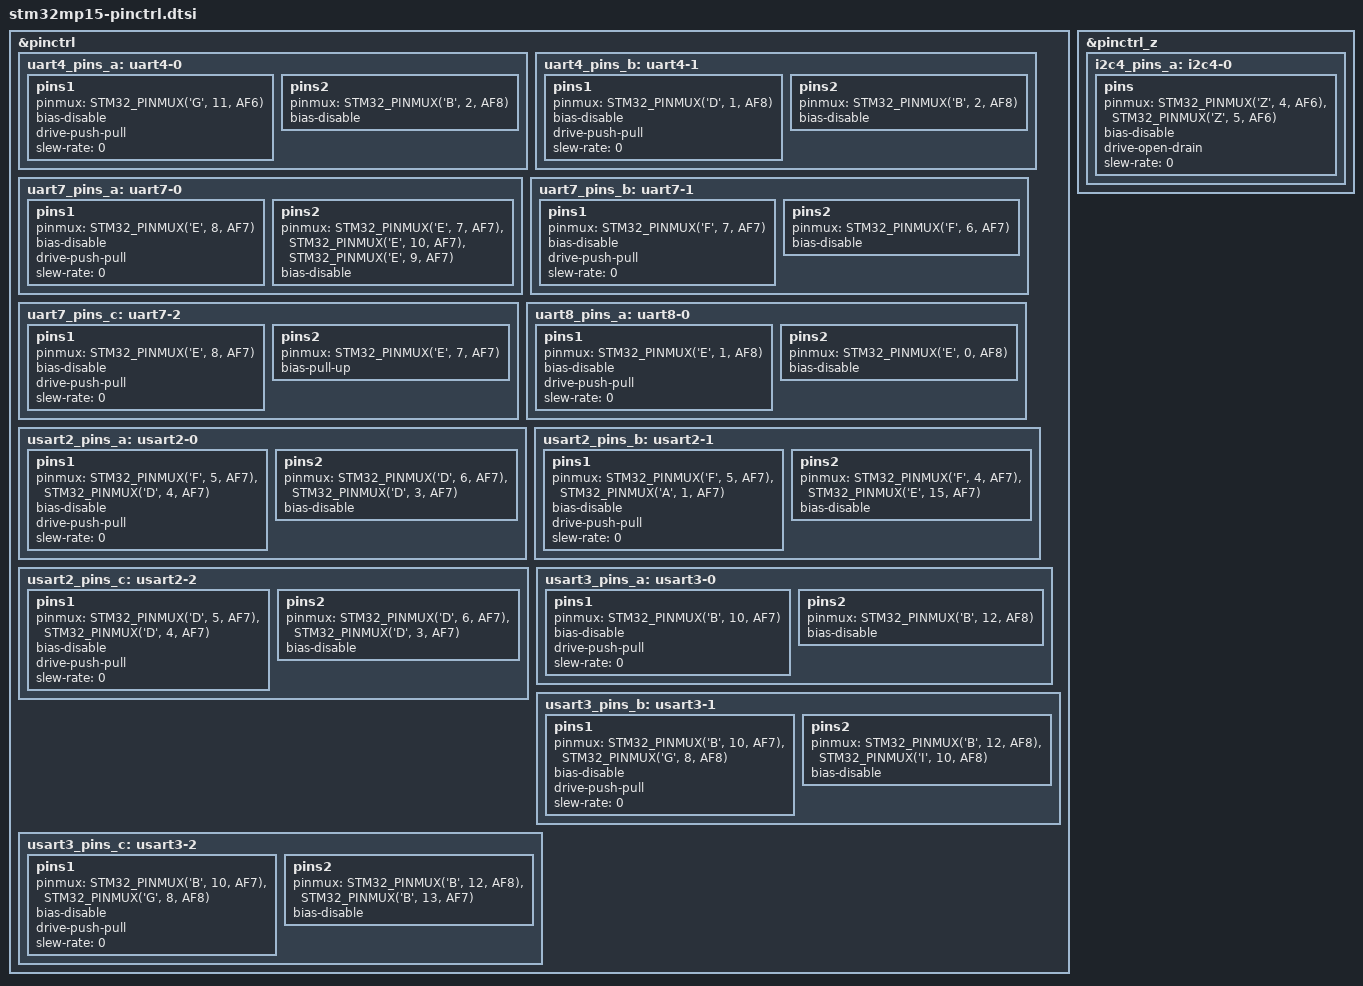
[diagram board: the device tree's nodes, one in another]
// SPDX-License-Identifier: (GPL-2.0+ OR BSD-3-Clause)
/*
 * Copyright (C) STMicroelectronics 2017 - All Rights Reserved
 * Author: Ludovic Barre <ludovic.barre@st.com> for STMicroelectronics.
 */
#include <dt-bindings/pinctrl/stm32-pinfunc.h>

&pinctrl {
	uart4_pins_a: uart4-0 {
		pins1 {
			pinmux = <STM32_PINMUX('G', 11, AF6)>; /* UART4_TX */
			bias-disable;
			drive-push-pull;
			slew-rate = <0>;
		};
		pins2 {
			pinmux = <STM32_PINMUX('B', 2, AF8)>; /* UART4_RX */
			bias-disable;
		};
	};

	uart4_pins_b: uart4-1 {
		pins1 {
			pinmux = <STM32_PINMUX('D', 1, AF8)>; /* UART4_TX */
			bias-disable;
			drive-push-pull;
			slew-rate = <0>;
		};
		pins2 {
			pinmux = <STM32_PINMUX('B', 2, AF8)>; /* UART4_RX */
			bias-disable;
		};
	};

	uart7_pins_a: uart7-0 {
		pins1 {
			pinmux = <STM32_PINMUX('E', 8, AF7)>; /* UART7_TX */
			bias-disable;
			drive-push-pull;
			slew-rate = <0>;
		};
		pins2 {
			pinmux = <STM32_PINMUX('E', 7, AF7)>, /* UART7_RX */
				 <STM32_PINMUX('E', 10, AF7)>, /* UART7_CTS */
				 <STM32_PINMUX('E', 9, AF7)>; /* UART7_RTS */
			bias-disable;
		};
	};

	uart7_pins_b: uart7-1 {
		pins1 {
			pinmux = <STM32_PINMUX('F', 7, AF7)>; /* UART7_TX */
			bias-disable;
			drive-push-pull;
			slew-rate = <0>;
		};
		pins2 {
			pinmux = <STM32_PINMUX('F', 6, AF7)>; /* UART7_RX */
			bias-disable;
		};
	};

	uart7_pins_c: uart7-2 {
		pins1 {
			pinmux = <STM32_PINMUX('E', 8, AF7)>; /* UART7_TX */
			bias-disable;
			drive-push-pull;
			slew-rate = <0>;
		};
		pins2 {
			pinmux = <STM32_PINMUX('E', 7, AF7)>; /* UART7_RX */
			bias-pull-up;
		};
	};

	uart8_pins_a: uart8-0 {
		pins1 {
			pinmux = <STM32_PINMUX('E', 1, AF8)>; /* UART8_TX */
			bias-disable;
			drive-push-pull;
			slew-rate = <0>;
		};
		pins2 {
			pinmux = <STM32_PINMUX('E', 0, AF8)>; /* UART8_RX */
			bias-disable;
		};
	};

	usart2_pins_a: usart2-0 {
		pins1 {
			pinmux = <STM32_PINMUX('F', 5, AF7)>, /* USART2_TX */
				 <STM32_PINMUX('D', 4, AF7)>; /* USART2_RTS */
			bias-disable;
			drive-push-pull;
			slew-rate = <0>;
		};
		pins2 {
			pinmux = <STM32_PINMUX('D', 6, AF7)>, /* USART2_RX */
				 <STM32_PINMUX('D', 3, AF7)>; /* USART2_CTS_NSS */
			bias-disable;
		};
	};

	usart2_pins_b: usart2-1 {
		pins1 {
			pinmux = <STM32_PINMUX('F', 5, AF7)>, /* USART2_TX */
				 <STM32_PINMUX('A', 1, AF7)>; /* USART2_RTS */
			bias-disable;
			drive-push-pull;
			slew-rate = <0>;
		};
		pins2 {
			pinmux = <STM32_PINMUX('F', 4, AF7)>, /* USART2_RX */
				 <STM32_PINMUX('E', 15, AF7)>; /* USART2_CTS_NSS */
			bias-disable;
		};
	};

	usart2_pins_c: usart2-2 {
		pins1 {
			pinmux = <STM32_PINMUX('D', 5, AF7)>, /* USART2_TX */
				 <STM32_PINMUX('D', 4, AF7)>; /* USART2_RTS */
			bias-disable;
			drive-push-pull;
			slew-rate = <0>;
		};
		pins2 {
			pinmux = <STM32_PINMUX('D', 6, AF7)>, /* USART2_RX */
				 <STM32_PINMUX('D', 3, AF7)>; /* USART2_CTS_NSS */
			bias-disable;
		};
	};

	usart3_pins_a: usart3-0 {
		pins1 {
			pinmux = <STM32_PINMUX('B', 10, AF7)>; /* USART3_TX */
			bias-disable;
			drive-push-pull;
			slew-rate = <0>;
		};
		pins2 {
			pinmux = <STM32_PINMUX('B', 12, AF8)>; /* USART3_RX */
			bias-disable;
		};
	};

	usart3_pins_b: usart3-1 {
		pins1 {
			pinmux = <STM32_PINMUX('B', 10, AF7)>, /* USART3_TX */
				 <STM32_PINMUX('G', 8, AF8)>; /* USART3_RTS */
			bias-disable;
			drive-push-pull;
			slew-rate = <0>;
		};
		pins2 {
			pinmux = <STM32_PINMUX('B', 12, AF8)>, /* USART3_RX */
				 <STM32_PINMUX('I', 10, AF8)>; /* USART3_CTS_NSS */
			bias-disable;
		};
	};

	usart3_pins_c: usart3-2 {
		pins1 {
			pinmux = <STM32_PINMUX('B', 10, AF7)>, /* USART3_TX */
				 <STM32_PINMUX('G', 8, AF8)>; /* USART3_RTS */
			bias-disable;
			drive-push-pull;
			slew-rate = <0>;
		};
		pins2 {
			pinmux = <STM32_PINMUX('B', 12, AF8)>, /* USART3_RX */
				 <STM32_PINMUX('B', 13, AF7)>; /* USART3_CTS_NSS */
			bias-disable;
		};
	};
};

&pinctrl_z {
	i2c4_pins_a: i2c4-0 {
		pins {
			pinmux = <STM32_PINMUX('Z', 4, AF6)>, /* I2C4_SCL */
				 <STM32_PINMUX('Z', 5, AF6)>; /* I2C4_SDA */
			bias-disable;
			drive-open-drain;
			slew-rate = <0>;
		};
	};
};
